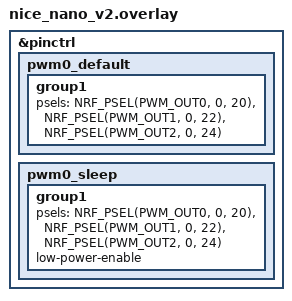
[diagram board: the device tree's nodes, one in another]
#include <dt-bindings/led/led.h>

&pinctrl {

    pwm0_default: pwm0_default {
        group1 {
            psels = <NRF_PSEL(PWM_OUT0, 0, 20)>, // LED 0
                    <NRF_PSEL(PWM_OUT1, 0, 22)>, // LED 1
                    <NRF_PSEL(PWM_OUT2, 0, 24)>; // LED 2
        };
    };
    pwm0_sleep: pwm0_sleep {
        group1 {
            psels = <NRF_PSEL(PWM_OUT0, 0, 20)>, // LED 0
                    <NRF_PSEL(PWM_OUT1, 0, 22)>, // LED 1
                    <NRF_PSEL(PWM_OUT2, 0, 24)>; // LED 2
            low-power-enable;
        };
    };
};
